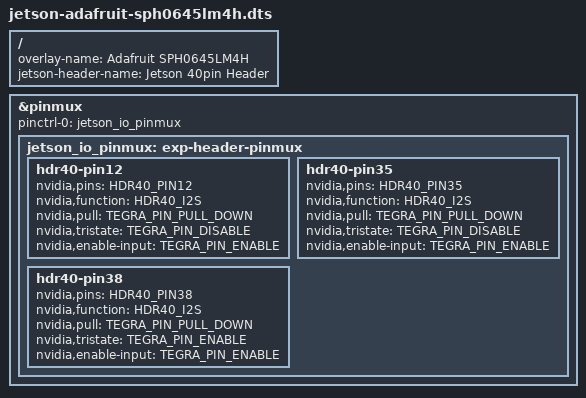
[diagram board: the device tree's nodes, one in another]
/*
 * Copyright (c) 2019-2021, NVIDIA CORPORATION.  All rights reserved.
 *
 * This program is free software; you can redistribute it and/or modify it
 * under the terms and conditions of the GNU General Public License,
 * version 2, as published by the Free Software Foundation.
 *
 * This program is distributed in the hope it will be useful, but WITHOUT
 * ANY WARRANTY; without even the implied warranty of MERCHANTABILITY or
 * FITNESS FOR A PARTICULAR PURPOSE.  See the GNU General Public License for
 * more details.
 *
 * You should have received a copy of the GNU General Public License
 * along with this program.  If not, see <http://www.gnu.org/licenses/>.
 */

/*
 * Jetson Device-tree overlay for Adafruit I2S MEMS Microphone Breakout
 * (SPH0645LM4H).
 */

#include <dt-bindings/pinctrl/pinctrl-tegra.h>

/ {
	overlay-name = "Adafruit SPH0645LM4H";
	jetson-header-name = "Jetson 40pin Header";
	compatible = JETSON_COMPATIBLE;

	fragment@0 {
		target = <&pinmux>;
		__overlay__ {
			pinctrl-names = "default";
			pinctrl-0 = <&jetson_io_pinmux>;

			jetson_io_pinmux: exp-header-pinmux {
				hdr40-pin12 {
					nvidia,pins = HDR40_PIN12;
					nvidia,function = HDR40_I2S;
					nvidia,pull = <TEGRA_PIN_PULL_DOWN>;
					nvidia,tristate = <TEGRA_PIN_DISABLE>;
					nvidia,enable-input = <TEGRA_PIN_ENABLE>;
				};

				hdr40-pin35 {
					nvidia,pins = HDR40_PIN35;
					nvidia,function = HDR40_I2S;
					nvidia,pull = <TEGRA_PIN_PULL_DOWN>;
					nvidia,tristate = <TEGRA_PIN_DISABLE>;
					nvidia,enable-input = <TEGRA_PIN_ENABLE>;
				};

				hdr40-pin38 {
					nvidia,pins = HDR40_PIN38;
					nvidia,function = HDR40_I2S;
					nvidia,pull = <TEGRA_PIN_PULL_DOWN>;
					nvidia,tristate = <TEGRA_PIN_ENABLE>;
					nvidia,enable-input = <TEGRA_PIN_ENABLE>;
				};
			};
		};
	};
};
